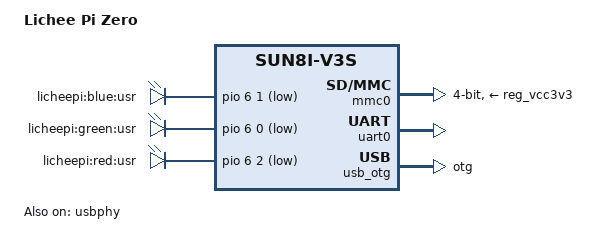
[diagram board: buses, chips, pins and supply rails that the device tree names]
/*
 * Copyright (C) 2016 Icenowy Zheng <icenowy@aosc.xyz>
 *
 * This file is dual-licensed: you can use it either under the terms
 * of the GPL or the X11 license, at your option. Note that this dual
 * licensing only applies to this file, and not this project as a
 * whole.
 *
 *  a) This file is free software; you can redistribute it and/or
 *     modify it under the terms of the GNU General Public License as
 *     published by the Free Software Foundation; either version 2 of the
 *     License, or (at your option) any later version.
 *
 *     This file is distributed in the hope that it will be useful,
 *     but WITHOUT ANY WARRANTY; without even the implied warranty of
 *     MERCHANTABILITY or FITNESS FOR A PARTICULAR PURPOSE.  See the
 *     GNU General Public License for more details.
 *
 * Or, alternatively,
 *
 *  b) Permission is hereby granted, free of charge, to any person
 *     obtaining a copy of this software and associated documentation
 *     files (the "Software"), to deal in the Software without
 *     restriction, including without limitation the rights to use,
 *     copy, modify, merge, publish, distribute, sublicense, and/or
 *     sell copies of the Software, and to permit persons to whom the
 *     Software is furnished to do so, subject to the following
 *     conditions:
 *
 *     The above copyright notice and this permission notice shall be
 *     included in all copies or substantial portions of the Software.
 *
 *     THE SOFTWARE IS PROVIDED "AS IS", WITHOUT WARRANTY OF ANY KIND,
 *     EXPRESS OR IMPLIED, INCLUDING BUT NOT LIMITED TO THE WARRANTIES
 *     OF MERCHANTABILITY, FITNESS FOR A PARTICULAR PURPOSE AND
 *     NONINFRINGEMENT. IN NO EVENT SHALL THE AUTHORS OR COPYRIGHT
 *     HOLDERS BE LIABLE FOR ANY CLAIM, DAMAGES OR OTHER LIABILITY,
 *     WHETHER IN AN ACTION OF CONTRACT, TORT OR OTHERWISE, ARISING
 *     FROM, OUT OF OR IN CONNECTION WITH THE SOFTWARE OR THE USE OR
 *     OTHER DEALINGS IN THE SOFTWARE.
 */

/dts-v1/;
#include "sun8i-v3s.dtsi"
#include "sunxi-common-regulators.dtsi"

/ {
	model = "Lichee Pi Zero";
	compatible = "licheepi,licheepi-zero", "allwinner,sun8i-v3s";

	aliases {
		serial0 = &uart0;
	};

	chosen {
		stdout-path = "serial0:115200n8";
	};

	leds {
		compatible = "gpio-leds";

		blue_led {
			label = "licheepi:blue:usr";
			gpios = <&pio 6 1 GPIO_ACTIVE_LOW>; /* PG1 */
		};

		green_led {
			label = "licheepi:green:usr";
			gpios = <&pio 6 0 GPIO_ACTIVE_LOW>; /* PG0 */
			default-state = "on";
		};

		red_led {
			label = "licheepi:red:usr";
			gpios = <&pio 6 2 GPIO_ACTIVE_LOW>; /* PG2 */
		};
	};
};

&mmc0 {
	broken-cd;
	bus-width = <4>;
	vmmc-supply = <&reg_vcc3v3>;
	status = "okay";
};

&uart0 {
	pinctrl-0 = <&uart0_pb_pins>;
	pinctrl-names = "default";
	status = "okay";
};

&usb_otg {
	dr_mode = "otg";
	status = "okay";
};

&usbphy {
	usb0_id_det-gpios = <&pio 5 6 GPIO_ACTIVE_HIGH>;
	status = "okay";
};
